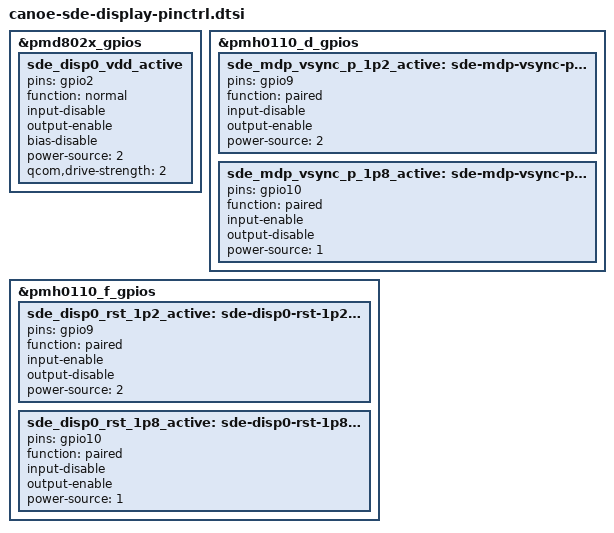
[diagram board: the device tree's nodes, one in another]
// SPDX-License-Identifier: BSD-3-Clause
/*
 * Copyright (c) Qualcomm Technologies, Inc. and/or its subsidiaries.
 */

&pmd802x_gpios {
	sde_disp0_vdd_active: sde_disp0_vdd_active {
		pins = "gpio2";
		function = "normal";
		input-disable;
		output-enable;
		bias-disable;
		power-source = <2>;
		qcom,drive-strength = <2>;
	};
};

/* TODO: define suspend states for these GPIOs and add them to pinctrl suspend state list */
&pmh0110_d_gpios {
	sde_mdp_vsync_p_1p2_active: sde-mdp-vsync-p-1p2-active-state {
		pins = "gpio9";
		function = "paired";
		input-disable;
		output-enable;
		power-source = <2>; /* 1.2v */
	};

	sde_mdp_vsync_p_1p8_active: sde-mdp-vsync-p-1p8-active-state {
		pins = "gpio10";
		function = "paired";
		input-enable;
		output-disable;
		power-source = <1>; /* 1.8v */
	};
};

&pmh0110_f_gpios {
	sde_disp0_rst_1p2_active: sde-disp0-rst-1p2-active-state {
		pins = "gpio9";
		function = "paired";
		input-enable;
		output-disable;
		power-source = <2>; /* 1.2v */
	};

	sde_disp0_rst_1p8_active: sde-disp0-rst-1p8-active-state {
		pins = "gpio10";
		function = "paired";
		input-disable;
		output-enable;
		power-source = <1>; /* 1.8v */
	};
};
